# STM32H5E4 register map
File version: 1.0
CPU: CM33 r0p0, little endian, MPU, FPU, 4 interrupt priority bits
Registers are 32-bit, read-write, reset 0x0 unless marked. A register's access mark holds for its fields unless they carry their own. Offsets are from the block's base; [hi:lo] are bit positions; lines under a group give offsets from that group; {n}, {i} and the like mark numbered series; 'fields as' and 'values as' point back to an identical list.

## FLASH — FLASH register block
Base 0x40022000
Same registers: FLASH_S 0x50022000
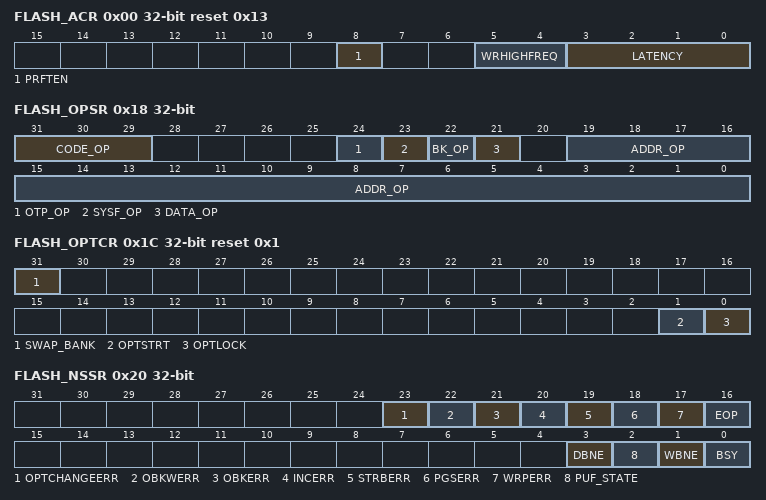
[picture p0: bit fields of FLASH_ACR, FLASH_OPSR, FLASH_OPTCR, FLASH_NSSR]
0x00 FLASH_ACR reset 0x13 — FLASH access control register
  [8] PRFTEN — Prefetch enable.
    0=prefetch disabled; 1=prefetch enabled when latency is at least one wait state
  [5:4] WRHIGHFREQ — Flash signal delay
  [3:0] LATENCY — Read latency
    0=no wait states used to read a word from nonvolatile memory; 1=one wait state used to read a word from nonvolatile memory; 2=two wait states used to read a word from nonvolatile memory; 7=seven wait states used to read a word from nonvolatile memory; 15=15 wait states used to read a word from nonvolatile memory
0x04 FLASH_NSKEYR wo — FLASH nonsecure key register
  [31:0] NSKEY — Non-volatile memory nonsecure configuration access unlock key
0x08 FLASH_SECKEYR wo — FLASH secure key register
  [31:0] SECKEY — Non-volatile memory secure configuration access unlock key
0x0C FLASH_OPTKEYR wo — FLASH option key register
  [31:0] OPTKEY — FLASH option bytes control access unlock key
0x10 FLASH_NSOBKKEYR wo — FLASH nonsecure OBK key register
  [31:0] NSOBKKEY — FLASH nonsecure option bytes keys control access unlock key
0x14 FLASH_SECOBKKEYR wo — FLASH secure OBK key register
  [31:0] SECOBKKEY — FLASH secure option bytes keys control access unlock key
0x18 FLASH_OPSR ro reset not defined — FLASH operation status register
  [31:29] CODE_OP — Flash memory operation code
    0=No flash operation ongoing during previous reset; 1=Single write operation interrupted; 2=OBK alternate sector erase; 3=Sector erase operation interrupted; 4=Bank erase operation interrupted; 5=Mass erase operation interrupted; 6=Option change operation interrupted; 7=OBK swap sector request
  [24] OTP_OP — OTP operation interrupted
  [23] SYSF_OP — Operation in system flash memory interrupted
  [22] BK_OP — Interrupted operation bank
  [21] DATA_OP — Flash high-cycle data area operation interrupted
  [19:0] ADDR_OP — Interrupted operation address
0x1C FLASH_OPTCR reset 0x1 (reset mask 0xFFFFFFF) — FLASH option control register
  [31] SWAP_BANK ro — Bank swapping option configuration bit
    0=Bank1 and bank2 not swapped; 1=Bank1 and bank2 swapped
  [1] OPTSTRT — Option byte start change option configuration bit
  [0] OPTLOCK — FLASH_OPTCR lock option configuration bit
    0=FLASH_OPTCR register unlocked; 1=FLASH_OPTCR register locked
0x20 FLASH_NSSR ro (reset mask 0xFFFFFFF0) — FLASH nonsecure status register
  [23] OPTCHANGEERR — Option byte change error flag
    0=no option byte change errors occurred; 1=one or more errors occurred during an option byte change operation
  [22] OBKWERR — OBK write error flag
    0=no OBK write error occurred; 1=an OBK write error occurred
  [21] OBKERR — OBK general error flag
    0=no OBK general error occurred; 1=an OBK general error occurred
  [20] INCERR — inconsistency error flag
    0=no inconsistency error occurs; 1=a inconsistency error occurs
  [19] STRBERR — strobe error flag
    0=no strobe error occurred; 1=a strobe error occurred
  [18] PGSERR — programming sequence error flag
    0=no sequence error occurred; 1=a sequence error occurred
  [17] WRPERR — write protection error flag
    0=no write protection error occurred; 1=a write protection error occurred
  [16] EOP — end of operation flag
    0=no operation completed; 1=a operation completed
  [3] DBNE — data buffer not empty flag
    0=data buffer not used; 1=data buffer used, wait
  [2] PUF_STATE — PUF readiness
    0=PUF is not ready; 1=PUF is ready for use
  [1] WBNE — write buffer not empty flag
    0=write buffer empty or full; 1=write buffer waiting data to complete
  [0] BSY — busy flag
    0=no programming, erase or option byte change operation being executed; 1=programming, erase or option byte change operation being executed
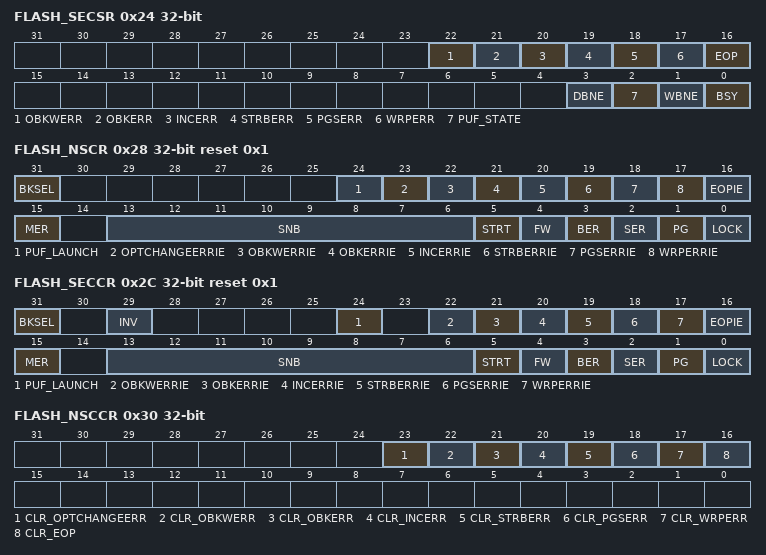
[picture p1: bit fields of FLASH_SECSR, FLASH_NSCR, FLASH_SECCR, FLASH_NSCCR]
0x24 FLASH_SECSR ro (reset mask 0xFFFFFFF0) — FLASH secure status register
  [22] OBKWERR — OBK write error flag
    0=no OBK write error occurred; 1=an OBK write error occurred
  [21] OBKERR — OBK general error flag
    values as FLASH_NSSR.OBKERR
  [20] INCERR — inconsistency error flag
    0=no inconsistency error occurred; 1=a inconsistency error occurred
  [19] STRBERR — strobe error flag
    0=no strobe error occurred; 1=a strobe error occurred
  [18] PGSERR — programming sequence error flag
    0=no sequence error occurred; 1=a sequence error occurred
  [17] WRPERR — write protection error flag
    values as FLASH_NSSR.WRPERR
  [16] EOP — end of operation flag
    0=no operation completed; 1=a operation completed
  [3] DBNE — data buffer not empty flag
    0=data buffer not used; 1=data buffer used, wait
  [2] PUF_STATE — PUF readiness
    0=PUF is not ready; 1=PUF is ready for use
  [1] WBNE — write buffer not empty flag
    values as FLASH_NSSR.WBNE
  [0] BSY — busy flag
    values as FLASH_NSSR.BSY
0x28 FLASH_NSCR reset 0x1 — FLASH nonsecure control register
  [31] BKSEL — Bank selector bit
    0=Bank1 is selected for Bank erase / sector erase / interrupt enable; 1=Bank2 is selected for BER / SER
  [24] PUF_LAUNCH — PUF preparation start control bit
  [23] OPTCHANGEERRIE — Option byte change error interrupt enable bit
    0=no interrupt is generated when an error occurs during an option byte change; 1=an interrupt is generated when and error occurs during an option byte change
  [22] OBKWERRIE — OBK write error interrupt enable bit
    0=no interrupt is generated on OBK write error; 1=an interrupt is generated on OBK write error
  [21] OBKERRIE — OBK general error interrupt enable bit
    0=no interrupt is generated on OBK general access error; 1=an interrupt is generated on OBK general access error
  [20] INCERRIE — inconsistency error interrupt enable bit
    0=no interrupt generated when a inconsistency error occurs; 1=interrupt generated when a inconsistency error occurs
  [19] STRBERRIE — strobe error interrupt enable bit
    0=no interrupt generated when a strobe error occurs; 1=interrupt generated when strobe error occurs
  [18] PGSERRIE — programming sequence error interrupt enable bit
    0=no interrupt generated when a sequence error occurs; 1=interrupt generated when sequence error occurs
  [17] WRPERRIE — write protection error interrupt enable bit
    0=no interrupt generated when a protection error occurs; 1=interrupt generated when a protection error occurs
  [16] EOPIE — end of operation interrupt control bit
    0=no interrupt generated at the end of operation; 1=interrupt enabled when at the end of operation
  [15] MER — mass erase request
    0=mass erase not requested; 1=mass erase requested
  [13:6] SNB — sector erase selection number
    0=Sector 0 selected; 1=Sector 1 selected; 255=Sector 255 selected
  [5] STRT — erase start control bit
  [4] FW — write forcing control bit
  [3] BER — erase request
    0=bank erase not requested; 1=bank erase requested
  [2] SER — sector erase request
    0=sector erase not requested; 1=sector erase requested
  [1] PG — programming control bit
    0=programming disabled; 1=programming enabled
  [0] LOCK — configuration lock bit
    0=FLASH_NSCR register unlocked; 1=FLASH_NSCR register locked
0x2C FLASH_SECCR reset 0x1 — FLASH secure control register
  [31] BKSEL — Bank selector bit
    0=Bank1 is selected for bank erase / sector erase / interrupt enable; 1=Bank2 is selected for BER / SER
  [29] INV — Flash memory security state invert.
  [24] PUF_LAUNCH — PUF preparation start control bit
  [22] OBKWERRIE — OBK write error interrupt enable bit
    values as FLASH_NSCR.OBKWERRIE
  [21] OBKERRIE — OBK general error interrupt enable bit
    values as FLASH_NSCR.OBKERRIE
  [20] INCERRIE — inconsistency error interrupt enable bit
    values as FLASH_NSCR.INCERRIE
  [19] STRBERRIE — strobe error interrupt enable bit
    values as FLASH_NSCR.STRBERRIE
  [18] PGSERRIE — programming sequence error interrupt enable bit
    values as FLASH_NSCR.PGSERRIE
  [17] WRPERRIE — write protection error interrupt enable bit
    values as FLASH_NSCR.WRPERRIE
  [16] EOPIE — end of operation interrupt control bit
    values as FLASH_NSCR.EOPIE
  [15] MER — mass erase request
    0=mass erase not requested; 1=mass erase requested
  [13:6] SNB — sector erase selection number
    values as FLASH_NSCR.SNB
  [5] STRT — erase start control bit
  [4] FW — write forcing control bit
  [3] BER — erase request
    0=bank erase not requested; 1=bank erase requested
  [2] SER — sector erase request
    0=sector erase not requested; 1=sector erase requested
  [1] PG — programming control bit
    0=programming disabled; 1=programming enabled
  [0] LOCK — configuration lock bit
    0=FLASH_SECCR register unlocked; 1=FLASH_SECCR register locked
0x30 FLASH_NSCCR wo — FLASH nonsecure clear control register
  [23] CLR_OPTCHANGEERR — Clear the flag corresponding flag in FLASH_NSSR by writing this bit.
  [22] CLR_OBKWERR — OBKWERR flag clear bit.
  [21] CLR_OBKERR — OBKERR flag clear bit.
  [20] CLR_INCERR — INCERR flag clear bit
  [19] CLR_STRBERR — STRBERR flag clear bit
  [18] CLR_PGSERR — PGSERR flag clear bit
  [17] CLR_WRPERR — WRPERR flag clear bit
  [16] CLR_EOP — EOP flag clear bit
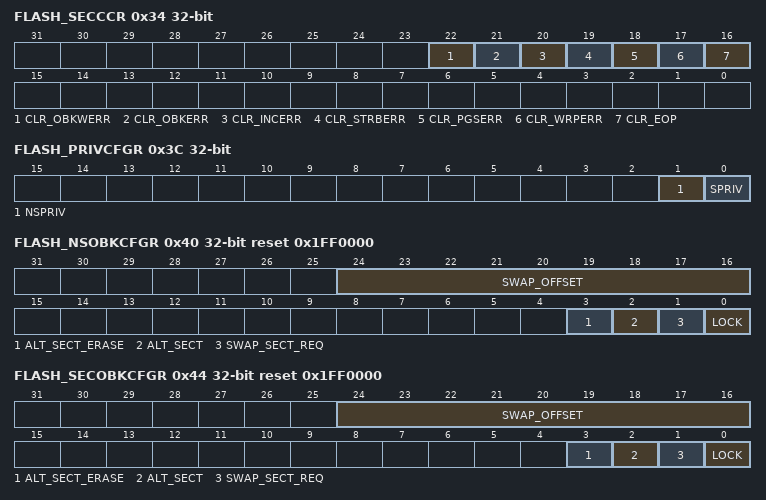
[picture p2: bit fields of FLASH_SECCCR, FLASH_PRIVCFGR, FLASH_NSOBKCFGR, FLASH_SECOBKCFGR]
0x34 FLASH_SECCCR wo — FLASH secure clear control register
  [22] CLR_OBKWERR — OBKWERR flag clear bit
  [21] CLR_OBKERR — OBKWERR flag clear bit
  [20] CLR_INCERR — INCERR flag clear bit
  [19] CLR_STRBERR — STRBERR flag clear bit
  [18] CLR_PGSERR — PGSERR flag clear bit
  [17] CLR_WRPERR — WRPERR flag clear bit
  [16] CLR_EOP — EOP flag clear bit
0x3C FLASH_PRIVCFGR — FLASH privilege configuration register
  [1] NSPRIV — privilege attribute for nonsecure registers
    0=access to nonsecure registers is always granted; 1=access to nonsecure registers is denied in case of unprivileged access
  [0] SPRIV — privilege attribute for secure registers
    0=access to secure registers is always granted; 1=access to secure registers is denied in case of unprivileged access
0x40 FLASH_NSOBKCFGR reset 0x1FF0000 — FLASH nonsecure OBK configuration register
  [24:16] SWAP_OFFSET — Key index (offset /16 bits) pointing for next swap.
    0=means that no OBK is copied from current to alternate OBK sector during SWAP operation; 0x1FF=means that all OBK data (511) are copied
  [3] ALT_SECT_ERASE — alternate sector erase bit
    0=do not touch OBK sector; 1=erase the alternate OBK sector
  [2] ALT_SECT — alternate sector bit
    0=current OBK sector is mapped to OBK address range for access; 1=alternate OBK sector is mapped to OBK address range for access
  [1] SWAP_SECT_REQ — OBK swap sector request bit
    0=no swap requested; 1=launch the sector swap
  [0] LOCK — OBKCFGR lock option configuration bit
    0=FLASH_NSOBKCFGR register unlocked; 1=FLASH_NSOBKCFGR register locked
0x44 FLASH_SECOBKCFGR reset 0x1FF0000 — FLASH secure OBK configuration register
  [24:16] SWAP_OFFSET — key index (offset /16 bits) pointing for next swap.
    0=no OBK is copied from current to alternate OBK sector during SWAP operation; 1=only the first OBK data (128 bits) are copied from current to alternate OBK sector; 2=the two first OBK data are copied; 0x1FF=the 511 first OBK data are copied
  [3] ALT_SECT_ERASE — alternate sector erase bit
    0=do not touch OBK sector; 1=erase the alternate OBK sector
  [2] ALT_SECT — alternate sector bit
    values as FLASH_NSOBKCFGR.ALT_SECT
  [1] SWAP_SECT_REQ — OBK swap sector request bit
    0=no swap requested; 1=launch the sector swap
  [0] LOCK — OBKCFGR lock option configuration bit
    0=FLASH_OBKCFGR register unlocked; 1=FLASH_OBKCFGR register locked
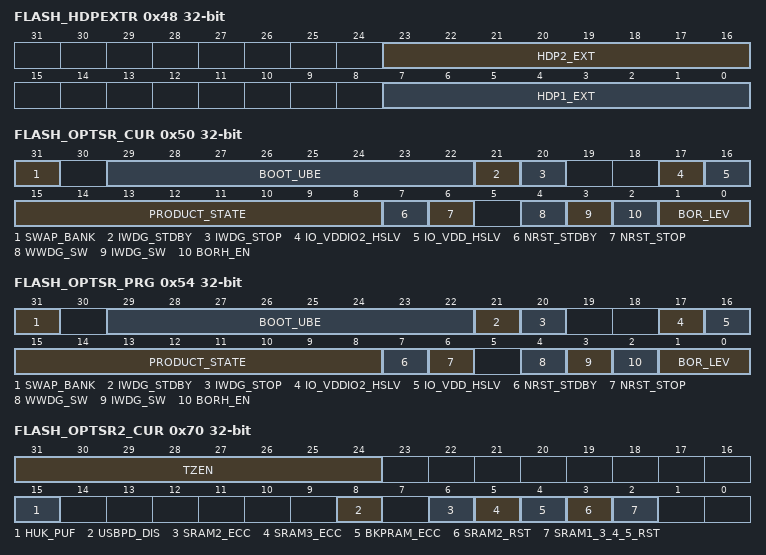
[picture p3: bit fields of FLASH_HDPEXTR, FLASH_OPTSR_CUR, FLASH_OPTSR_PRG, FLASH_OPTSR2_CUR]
0x48 FLASH_HDPEXTR — FLASH HDP extension register
  [23:16] HDP2_EXT — HDP area extension in 8Kbytes sectors in bank2.
  [7:0] HDP1_EXT — HDP area extension in 8Kbytes sectors in bank1.
0x50 FLASH_OPTSR_CUR ro reset not defined — FLASH option status register
  [31] SWAP_BANK — Bank swapping option status bit
    0=Bank1 and bank2 not swapped; 1=Bank1 and bank2 swapped
  [29:22] BOOT_UBE — Available only on cryptography enabled devices.
    195=ST-iRoT (system flash) selected; 180=OEM-iRoT (user flash) selected
  [21] IWDG_STDBY — IWDG Standby mode freeze option status bit
    0=Independent watchdog frozen in Standby mode; 1=Independent watchdog keep running in Standby mode
  [20] IWDG_STOP — IWDG Stop mode freeze option status bit
    0=Independent watchdog frozen in system Stop mode; 1=Independent watchdog keep running in system Stop mode
  [17] IO_VDDIO2_HSLV — High-speed IO at low Vless thansub>DDIO2less than/sub> voltage configuration bit.
    0=High-speed IO at low Vless thansub>DDIO2less than/sub> voltage feature disabled (Vless thansub>DDIO2less than/sub> can exceed 2; 1=High-speed IO at low Vless thansub>DDIO2less than/sub> voltage feature enabled (Vless thansub>DDIO2less than/sub> remains below 2
  [16] IO_VDD_HSLV — High-speed IO at low Vless thansub>DDless than/sub> voltage configuration bit.
    0=High-speed IO at low Vless thansub>DDless than/sub> voltage feature disabled (Vless thansub>DDless than/sub> can exceed 2; 1=High-speed IO at low Vless thansub>DDless than/sub> voltage feature enabled (Vless thansub>DDless than/sub> remains below 2
  [15:8] PRODUCT_STATE — Life state code (based on Hamming 8,4).
  [7] NRST_STDBY — Core domain Standby entry reset option status bit
    0=a reset is generated when entering Standby mode on core domain; 1=no reset generated when entering Standby mode on core domain
  [6] NRST_STOP — Core domain Stop entry reset option status bit
    0=a reset is generated when entering Stop mode on core domain; 1=no reset generated when entering Stop mode on core domain
  [4] WWDG_SW — WWDG control mode option status bit
    0=WWDG watchdog is controlled by hardware; 1=WWDG watchdog is controlled by software
  [3] IWDG_SW — IWDG control mode option status bit
    0=IWDG watchdog is controlled by hardware; 1=IWDG watchdog is controlled by software
  [2] BORH_EN — Brownout high enable
    0=disable; 1=enable
  [1:0] BOR_LEV — Brownout level option status bit
    1=BOR Level 2, the threshold level is medium (around 2; 2=BOR Level 3, the threshold level is high (around 2
0x54 FLASH_OPTSR_PRG reset not defined — FLASH option status register
  [31] SWAP_BANK — Bank swapping option configuration bit
    0=Bank1 and bank2 not swapped; 1=Bank1 and bank2 swapped
  [29:22] BOOT_UBE — Available only on cryptography enabled devices.
    values as FLASH_OPTSR_CUR.BOOT_UBE
  [21] IWDG_STDBY — IWDG Standby mode freeze option status bit
    values as FLASH_OPTSR_CUR.IWDG_STDBY
  [20] IWDG_STOP — IWDG Stop mode freeze option status bit
    values as FLASH_OPTSR_CUR.IWDG_STOP
  [17] IO_VDDIO2_HSLV — High-speed IO at low Vless thansub>DDIO2less than/sub> voltage configuration bit.
    values as FLASH_OPTSR_CUR.IO_VDDIO2_HSLV
  [16] IO_VDD_HSLV — High-speed IO at low VDD voltage configuration bit.
    values as FLASH_OPTSR_CUR.IO_VDD_HSLV
  [15:8] PRODUCT_STATE — Life state code (based on Hamming 8,4).
  [7] NRST_STDBY — Core domain Standby entry reset option configuration bit
    values as FLASH_OPTSR_CUR.NRST_STDBY
  [6] NRST_STOP — Core domain Stop entry reset option configuration bit
    values as FLASH_OPTSR_CUR.NRST_STOP
  [4] WWDG_SW — WWDG control mode option configuration bit
    values as FLASH_OPTSR_CUR.WWDG_SW
  [3] IWDG_SW — IWDG control mode option configuration bit
    values as FLASH_OPTSR_CUR.IWDG_SW
  [2] BORH_EN — Brownout high enable configuration bit
    0=disabled; 1=enabled
  [1:0] BOR_LEV — Brownout level option configuration bit
    values as FLASH_OPTSR_CUR.BOR_LEV
0x60 FLASH_NSEPOCHR_CUR ro reset not defined — FLASH nonsecure EPOCH register
  [23:0] NS_EPOCH — Non-volatile nonsecure EPOCH counter
0x68 FLASH_SECEPOCHR_CUR ro reset not defined — FLASH secure EPOCH register
  [23:0] SEC_EPOCH — Non-volatile secure EPOCH counter
0x70 FLASH_OPTSR2_CUR ro reset not defined — FLASH option status register 2
  [31:24] TZEN — TrustZone enable configuration bits
    195=TrustZone disabled; 180=TrustZone enabled
  [15] HUK_PUF — This bit select the source of the HUK sent to the SAES.
    0=Source is RHUK; 1=Source is PUF
  [8] USBPD_DIS — USB power delivery configuration option bit
    0=Enabled; 1=Disabled
  [6] SRAM2_ECC — SRAM2 ECC detection and correction disable
    0=SRAM2 ECC check enabled; 1=SRAM2 ECC check disabled
  [5] SRAM3_ECC — SRAM3 ECC detection and correction disable
    0=SRAM3 ECC check enabled; 1=SRAM3 ECC check disabled
  [4] BKPRAM_ECC — Backup RAM ECC detection and correction disable
    0=BKPRAM ECC check enabled; 1=BKPRAM ECC check disabled
  [3] SRAM2_RST — SRAM2 erase when system reset
    0=SRAM2 erased when a system reset occurs; 1=SRAM2 not erased when a system reset occurs
  [2] SRAM1_3_4_5_RST — SRAM1, SRAM3, SRAM4, and SRAM5 erase upon system reset
    0=SRAM1, SRAM3, SRAM4, and SRAM5 erased when a system reset occurs; 1=SRAM1, SRAM3, SRAM4, and SRAM5 not erased when a system reset occurs
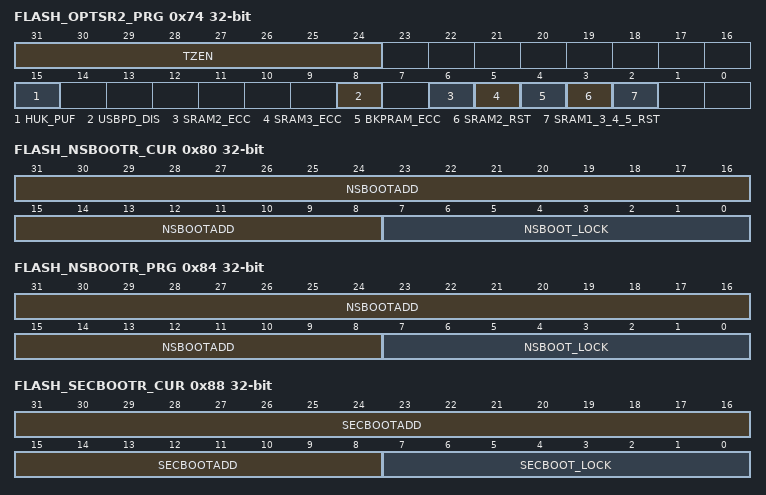
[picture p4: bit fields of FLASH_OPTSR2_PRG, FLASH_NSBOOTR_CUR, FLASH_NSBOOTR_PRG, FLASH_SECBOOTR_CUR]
0x74 FLASH_OPTSR2_PRG reset not defined — FLASH option status register 2
  [31:24] TZEN — TrustZone enable configuration bits
    195=TrustZone disabled; 180=TrustZone enabled
  [15] HUK_PUF ro — This bit select the source of the HUK sent to the SAES.
    0=Source is RHUK; 1=Source is PUF
  [8] USBPD_DIS — USB power delivery configuration option bit
    0=Enabled; 1=Disabled
  [6] SRAM2_ECC — SRAM2 ECC detection and correction disable
    0=SRAM2 ECC check enabled; 1=SRAM2 ECC check disabled
  [5] SRAM3_ECC — SRAM3 ECC detection and correction disable
    0=SRAM3 ECC check enabled; 1=SRAM3 ECC check disabled
  [4] BKPRAM_ECC — Backup RAM ECC detection and correction disable
    0=BKPRAM ECC check enabled; 1=BKPRAM ECC check disabled
  [3] SRAM2_RST — SRAM2 erase when system reset
    values as FLASH_OPTSR2_CUR.SRAM2_RST
  [2] SRAM1_3_4_5_RST — SRAM1, SRAM3, SRAM4, and SRAM5 erase upon system reset
    values as FLASH_OPTSR2_CUR.SRAM1_3_4_5_RST
0x80 FLASH_NSBOOTR_CUR ro reset not defined — FLASH nonsecure boot register
  [31:8] NSBOOTADD — Nonsecure unique boot entry address
  [7:0] NSBOOT_LOCK — Field locking the values of SWAP_BANK, and NSBOOTADD settings.
    195=SWAP_BANK and NSBOOTADD can still be modified following their individual rules; 180=NSBOOTADD is frozen
0x84 FLASH_NSBOOTR_PRG reset not defined — FLASH nonsecure boot register
  [31:8] NSBOOTADD — Nonsecure unique boot entry address
  [7:0] NSBOOT_LOCK — Field locking the values of SWAP_ BANK, and NSBOOTADD settings.
    195=SWAP_ BANK and NSBOOTADD can still be modified following their individual rules; 180=NSBOOTADD is frozen
0x88 FLASH_SECBOOTR_CUR ro reset not defined — FLASH secure boot register
  [31:8] SECBOOTADD — Unique boot entry secure address
  [7:0] SECBOOT_LOCK — Field locking the values of UBE, SWAP_BANK, and SECBOOTADD settings.
    195=BOOT_UBE, SWAP_BANK and SECBOOTADD can still be modified following their individual rules; 180=BOOT_UBE and SECBOOTADD are frozen
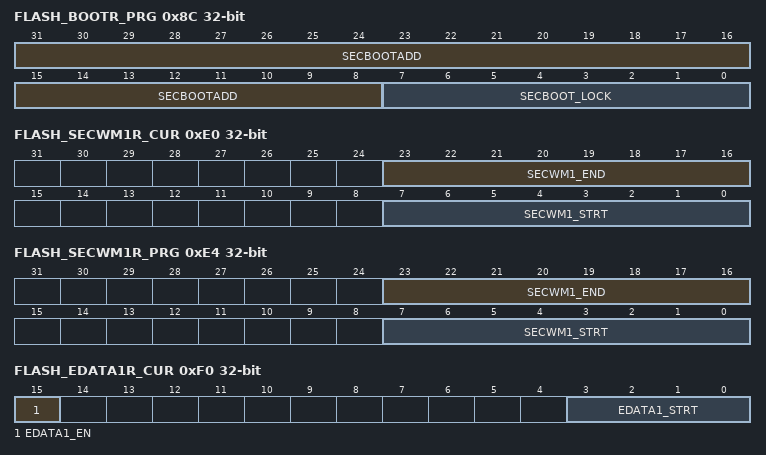
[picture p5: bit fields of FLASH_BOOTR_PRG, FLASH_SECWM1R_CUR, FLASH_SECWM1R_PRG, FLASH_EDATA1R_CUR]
0x8C FLASH_BOOTR_PRG reset not defined — FLASH secure boot register
  [31:8] SECBOOTADD — Secure unique boot entry address.
  [7:0] SECBOOT_LOCK — Field locking the values of UBE, SWAP_ BANK, and SECBOOTADD setting.
    195=BOOT_UBE, SWAP_ BANK and SECBOOTADD can still be modified following their individual rules; 180=BOOT_UBE and SECBOOTADD are frozen
0x90 FLASH_OTPBLR_CUR ro reset not defined — FLASH nonsecure OTP block lock
  [31:0] LOCKBL — OTP block lock
0x94 FLASH_OTPBLR_PRG reset not defined — FLASH nonsecure OTP block lock
  [31:0] LOCKBL — OTP block lock
0x98 FLASH_WRP12R_CUR ro reset not defined — FLASH write sector group 2 protection for bank1
  [31:0] WRPSG12 — Bank1 sector group 2 protection option status byte
0x9C FLASH_WRP12R_PRG reset not defined — FLASH write sector group 2 protection for bank1
  [31:0] WRPSG12 — Bank1 sector group 2 protection option status byte
{0x9C+4i} FLASH_SECBB1R{i} (i=1..8) — FLASH secure block based register for bank1
  [31:0] SECBB1 — Secure/nonsecure 8Kbytes flash bank1 sector attributes
    0=sector (32 * (x-1) + y) in bank1 is nonsecure; 1=sector (32 * (x-1) + y) in bank1 is secure
{0xBC+4i} FLASH_PRIVBB1R{i} (i=1..8) — FLASH privilege block based register for bank1
  [31:0] PRIVBB1 — Privileged/unprivileged 8-Kbyte flash bank1 sector attribute
    0=sectors (32 * (x-1) + y) in bank1 is unprivileged; 1=sector (32 * (x-1) + y) in bank1 is privileged
0xE0 FLASH_SECWM1R_CUR ro (reset mask 0xFF00FF00) — FLASH security watermark for bank1
  [23:16] SECWM1_END — bank1 security WM area 1 end sector
  [7:0] SECWM1_STRT — bank1 security WM area 1 start sector
0xE4 FLASH_SECWM1R_PRG (reset mask 0xFF00FF00) — FLASH security watermark for bank1
  fields as FLASH_SECWM1R_CUR
0xE8 FLASH_WRP11R_CUR ro reset not defined — FLASH write sector group 1 protection for bank1
  [31:0] WRPSG11 — bank1 sector group 1 protection option status byte
0xEC FLASH_WRP11R_PRG reset not defined — FLASH write sector group 1 protection for bank1
  [31:0] WRPSG11 — Bank1 sector group 1 protection option status byte
0xF0 FLASH_EDATA1R_CUR ro reset not defined — FLASH data sector configuration bank1
  [15] EDATA1_EN — Bank1 flash high-cycle data enable
    0=No flash high-cycle data area; 1=Flash high-cycle data is used
  [3:0] EDATA1_STRT — EDATA1_STRT contains the start sectors of the flash high-cycle data area in bank1.
    0=The last sector of bank1 is reserved for flash high-cycle data; 1=The two last sectors of bank1 are reserved for flash high-cycle data; 2=The three last sectors of bank1 are reserved for flash high-cycle data; 15=The sixteen last sectors of bank1 are reserved for flash high-cycle data
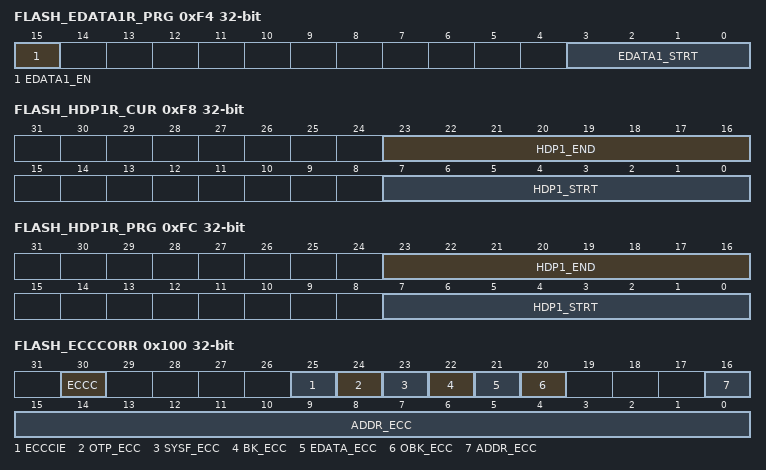
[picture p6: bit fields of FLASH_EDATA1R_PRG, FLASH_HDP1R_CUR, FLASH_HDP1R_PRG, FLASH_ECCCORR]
0xF4 FLASH_EDATA1R_PRG reset not defined — FLASH data sector configuration bank1
  [15] EDATA1_EN — Bank1 flash high-cycle data enable
    values as FLASH_EDATA1R_CUR.EDATA1_EN
  [3:0] EDATA1_STRT — EDATA1_STRT contains the start sectors of the flash high-cycle data area in bank1.
    0=The last sector of the bank1 is reserved for flash high-cycle data; 1=The two last sectors of the bank1 are reserved for flash high-cycle data; 2=The three last sectors of the bank1 are reserved for flash high-cycle data
0xF8 FLASH_HDP1R_CUR ro reset not defined — FLASH HDP bank1 configuration
  [23:16] HDP1_END — HDPL barrier end set in number of 8-Kbyte sectors
  [7:0] HDP1_STRT — HDPL barrier start set in number of 8-Kbyte sectors
0xFC FLASH_HDP1R_PRG reset not defined — FLASH HDP bank1 configuration
  fields as FLASH_HDP1R_CUR
0x100 FLASH_ECCCORR — FLASH ECC correction register
  [30] ECCC — ECC correction set by hardware when single ECC error has been detected and corrected.
  [25] ECCCIE — ECC single correction error interrupt enable bit
    0=no interrupt generated when an ECC single correction error occurs; 1=nonsecure interrupt generated when an ECC single correction error occurs
  [24] OTP_ECC ro — OTP ECC error bit
  [23] SYSF_ECC ro — ECC fail for corrected ECC error in system flash memory
  [22] BK_ECC ro — ECC fail bank for corrected ECC error
  [21] EDATA_ECC ro — ECC fail for corrected ECC error in flash high-cycle data area
  [20] OBK_ECC ro — Single ECC error corrected in flash OB Keys storage area.
  [16:0] ADDR_ECC ro — ECC error address
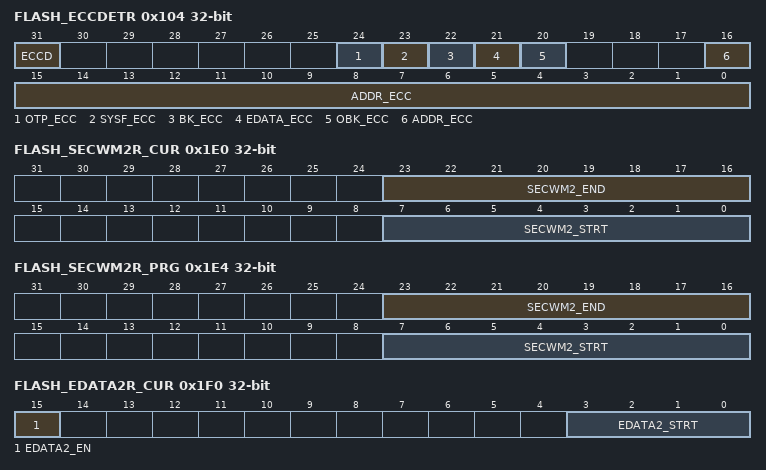
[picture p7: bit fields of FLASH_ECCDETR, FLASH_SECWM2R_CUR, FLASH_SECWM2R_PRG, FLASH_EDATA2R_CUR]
0x104 FLASH_ECCDETR — FLASH ECC detection register
  [31] ECCD — ECC detection
  [24] OTP_ECC ro — OTP ECC error bit
  [23] SYSF_ECC ro — ECC fail for double ECC error in system flash memory
  [22] BK_ECC ro — ECC fail bank for double ECC error
  [21] EDATA_ECC ro — ECC fail double ECC error in flash high-cycle data area
  [20] OBK_ECC ro — ECC fail double ECC error in flash OB Keys storage area.
  [16:0] ADDR_ECC ro — ECC error address
0x108 FLASH_ECCDR ro — FLASH ECC data
  [15:0] DATA_ECC — ECC error data
0x198 FLASH_WRP22R_CUR ro reset not defined — FLASH write sector group 2 protection for bank2
  [31:0] WRPSG22 — Bank2 sector group protection option status byte
0x19C FLASH_WRP22R_PRG reset not defined — FLASH write sector group 2 protection for bank2
  [31:0] WRPSG22 — Bank2 sector group protection option status byte
{0x19C+4i} FLASH_SECBB2R{i} (i=1..8) — FLASH secure block-based register for bank2
  [31:0] SECBB2 — Secure/nonsecure flash bank2 sector attribute
    0=sectors (32 * (x-1) + y) in bank2 is nonsecure; 1=sector (32 * (x-1) + y) in bank2 is secure
{0x1BC+4i} FLASH_PRIVBB2R{i} (i=1..8) — FLASH privilege block-based register for bank2
  [31:0] PRIVBB2 — Privileged / non-privileged 8-Kbyte flash bank2 sector attribute
    0=sectors (32 * (x-1) + y) in bank2 is unprivileged; 1=sector (32 * (x-1) + y) in bank2 is privileged
0x1E0 FLASH_SECWM2R_CUR ro (reset mask 0xFF00FF00) — FLASH security watermark for bank2
  [23:16] SECWM2_END — Bank2 security WM end sector
  [7:0] SECWM2_STRT — Bank2 security WM area start sector
0x1E4 FLASH_SECWM2R_PRG (reset mask 0xFF00FF00) — FLASH security watermark for bank2
  [23:16] SECWM2_END — Bank2 security WM area end sector
  [7:0] SECWM2_STRT — Bank2 security WM area start sector
0x1E8 FLASH_WRP21R_CUR ro reset not defined — FLASH write sector group 1 protection for bank2
  [31:0] WRPSG21 — Bank2 sector group 1 protection option status byte
0x1EC FLASH_WRP21R_PRG reset not defined — FLASH write sector group 1 protection for bank2
  [31:0] WRPSG21 — Bank2 sector group 1 protection option status byte
0x1F0 FLASH_EDATA2R_CUR ro reset not defined — FLASH data sectors configuration bank2
  [15] EDATA2_EN — Bank2 flash high-cycle data enable
    values as FLASH_EDATA1R_CUR.EDATA1_EN
  [3:0] EDATA2_STRT — EDATA2_STRT contains the start sectors of the flash high-cycle data area in bank2 There is no hardware effect to those bits.
    0=The last sector of bank2 is reserved for flash high-cycle data; 1=The two last sectors of bank2 are reserved for flash high-cycle data; 2=The three last sectors of bank2 are reserved for flash high-cycle data
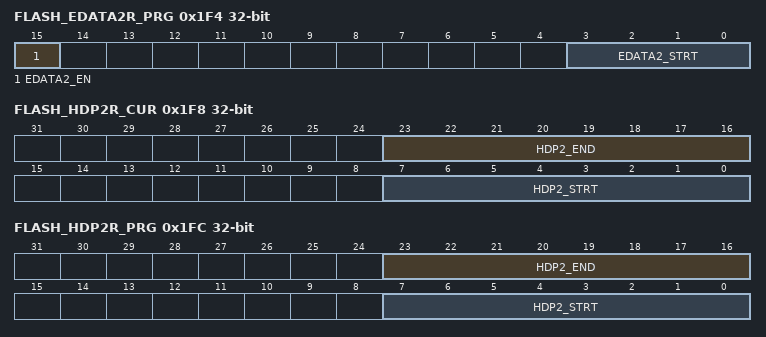
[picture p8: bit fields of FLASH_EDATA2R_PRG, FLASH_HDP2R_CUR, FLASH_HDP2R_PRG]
0x1F4 FLASH_EDATA2R_PRG reset not defined — FLASH data sector configuration bank2
  [15] EDATA2_EN — bank2 flash high-cycle data enable
    values as FLASH_EDATA1R_CUR.EDATA1_EN
  [3:0] EDATA2_STRT — EDATA2_STRT contains the start sectors of the flash high-cycle data area in bank2 There is no hardware effect to those bits.
    values as FLASH_EDATA2R_CUR.EDATA2_STRT
0x1F8 FLASH_HDP2R_CUR ro reset not defined — FLASH HDP bank2 configuration
  [23:16] HDP2_END — HDPL barrier end set in number of 8-Kbyte sectors
  [7:0] HDP2_STRT — HDPL barrier start set in number of 8-Kbyte sectors
0x1FC FLASH_HDP2R_PRG reset not defined — FLASH HDP bank2 configuration
  fields as FLASH_HDP2R_CUR
